VERSION ""

NS_ :

BS_:

BU_: MC_BRUSHED LISTENER COMMANDER REQUESTER

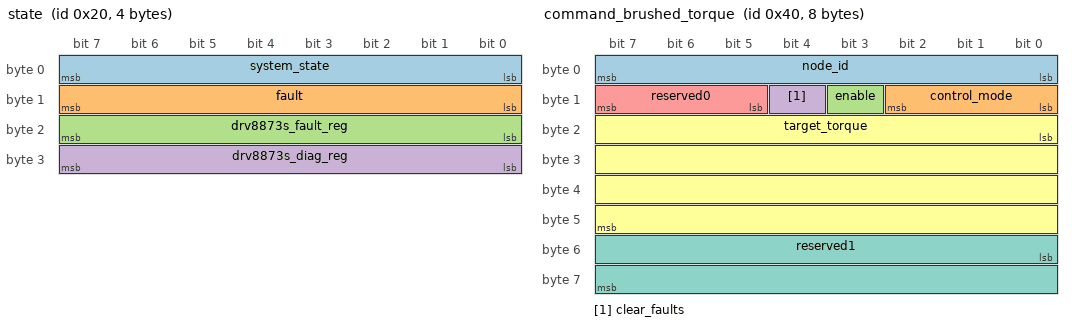
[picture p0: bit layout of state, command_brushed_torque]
BO_ 32 state: 4 MC_BRUSHED
 SG_ system_state : 0|8@1+ (1,0) [0|255] ""  LISTENER
 SG_ fault : 8|8@1+ (1,0) [0|255] ""  LISTENER
 SG_ drv8873s_fault_reg : 16|8@1+ (1,0) [0|255] ""  LISTENER
 SG_ drv8873s_diag_reg : 24|8@1+ (1,0) [0|255] ""  LISTENER

BO_ 64 command_brushed_torque: 8 COMMANDER
 SG_ node_id : 0|8@1+ (1,0) [0|255] ""  MC_BRUSHED
 SG_ control_mode : 8|3@1+ (1,0) [0|7] ""  MC_BRUSHED
 SG_ enable : 11|1@1+ (1,0) [0|1] ""  MC_BRUSHED
 SG_ clear_faults : 12|1@1+ (1,0) [0|1] ""  MC_BRUSHED
 SG_ reserved0 : 13|3@1+ (1,0) [0|7] ""  MC_BRUSHED
 SG_ target_torque : 16|32@1- (0.0001,0) [-214748.3648|214748.3647] "Nm"  MC_BRUSHED
 SG_ reserved1 : 48|16@1+ (1,0) [0|65535] ""  MC_BRUSHED

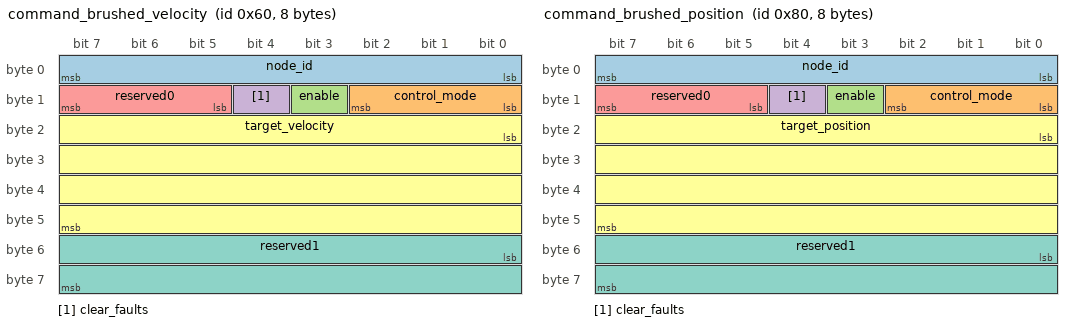
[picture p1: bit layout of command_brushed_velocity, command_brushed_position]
BO_ 96 command_brushed_velocity: 8 COMMANDER
 SG_ node_id : 0|8@1+ (1,0) [0|255] ""  MC_BRUSHED
 SG_ control_mode : 8|3@1+ (1,0) [0|7] ""  MC_BRUSHED
 SG_ enable : 11|1@1+ (1,0) [0|1] ""  MC_BRUSHED
 SG_ clear_faults : 12|1@1+ (1,0) [0|1] ""  MC_BRUSHED
 SG_ reserved0 : 13|3@1+ (1,0) [0|7] ""  MC_BRUSHED
 SG_ target_velocity : 16|32@1- (0.001,0) [-2147483.648|2147483.647] "rad/s"  MC_BRUSHED
 SG_ reserved1 : 48|16@1+ (1,0) [0|65535] ""  MC_BRUSHED

BO_ 128 command_brushed_position: 8 COMMANDER
 SG_ node_id : 0|8@1+ (1,0) [0|255] ""  MC_BRUSHED
 SG_ control_mode : 8|3@1+ (1,0) [0|7] ""  MC_BRUSHED
 SG_ enable : 11|1@1+ (1,0) [0|1] ""  MC_BRUSHED
 SG_ clear_faults : 12|1@1+ (1,0) [0|1] ""  MC_BRUSHED
 SG_ reserved0 : 13|3@1+ (1,0) [0|7] ""  MC_BRUSHED
 SG_ target_position : 16|32@1- (0.001,0) [-2147483.648|2147483.647] "rad"  MC_BRUSHED
 SG_ reserved1 : 48|16@1+ (1,0) [0|65535] ""  MC_BRUSHED

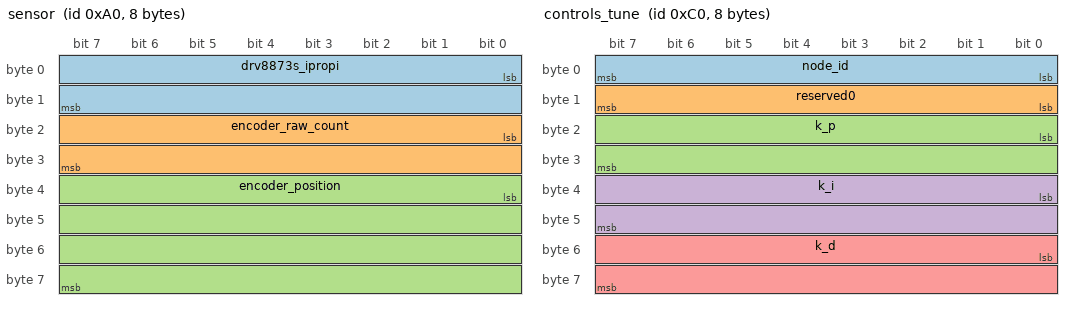
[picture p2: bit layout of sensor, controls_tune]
BO_ 160 sensor: 8 MC_BRUSHED
 SG_ drv8873s_ipropi : 0|16@1+ (1,0) [0|4095] "count"  LISTENER
 SG_ encoder_raw_count : 16|16@1- (1,0) [-32768|32767] "count"  LISTENER
 SG_ encoder_position : 32|32@1- (0.001,0) [-2147483.648|2147483.647] "rad"  LISTENER

BO_ 192 controls_tune: 8 COMMANDER
 SG_ node_id : 0|8@1+ (1,0) [0|255] ""  MC_BRUSHED
 SG_ reserved0 : 8|8@1+ (1,0) [0|255] ""  MC_BRUSHED
 SG_ k_p : 16|16@1+ (0.001,0) [0|65.535] ""  MC_BRUSHED
 SG_ k_i : 32|16@1+ (0.001,0) [0|65.535] ""  MC_BRUSHED
 SG_ k_d : 48|16@1+ (0.001,0) [0|65.535] ""  MC_BRUSHED

BO_ 224 controls_tune_get: 1 REQUESTER
 SG_ node_id : 0|8@1+ (1,0) [0|255] ""  MC_BRUSHED

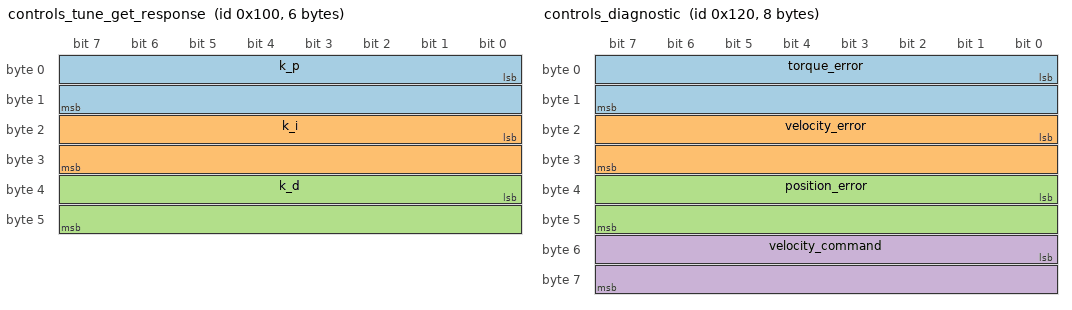
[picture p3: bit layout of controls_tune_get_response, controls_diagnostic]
BO_ 256 controls_tune_get_response: 6 MC_BRUSHED
 SG_ k_p : 0|16@1+ (0.001,0) [0|65.535] ""  REQUESTER
 SG_ k_i : 16|16@1+ (0.001,0) [0|65.535] ""  REQUESTER
 SG_ k_d : 32|16@1+ (0.001,0) [0|65.535] ""  REQUESTER

BO_ 288 controls_diagnostic: 8 MC_BRUSHED
 SG_ torque_error : 0|16@1- (0.001,0) [-32.768|32.767] "Nm"  LISTENER
 SG_ velocity_error : 16|16@1- (0.001,0) [-32.768|32.767] "rad/s"  LISTENER
 SG_ position_error : 32|16@1- (0.0001,0) [-3.2768|3.2767] "rad"  LISTENER
 SG_ velocity_command : 48|16@1- (0.001,0) [-32.768|32.767] "rad/s"  LISTENER

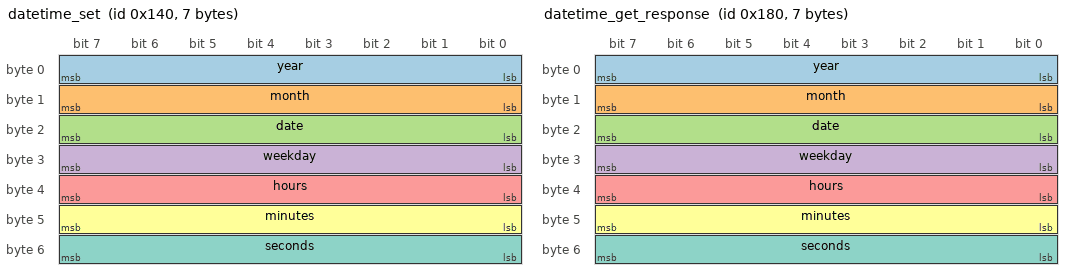
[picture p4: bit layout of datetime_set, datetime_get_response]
BO_ 320 datetime_set: 7 COMMANDER
 SG_ year : 0|8@1+ (1,0) [0|99] "year"  MC_BRUSHED
 SG_ month : 8|8@1+ (1,0) [1|12] "month"  MC_BRUSHED
 SG_ date : 16|8@1+ (1,0) [1|31] "day"  MC_BRUSHED
 SG_ weekday : 24|8@1+ (1,0) [1|7] "weekday"  MC_BRUSHED
 SG_ hours : 32|8@1+ (1,0) [0|23] "hour"  MC_BRUSHED
 SG_ minutes : 40|8@1+ (1,0) [0|59] "min"  MC_BRUSHED
 SG_ seconds : 48|8@1+ (1,0) [0|59] "sec"  MC_BRUSHED

BO_ 352 datetime_get: 0 REQUESTER

BO_ 384 datetime_get_response: 7 MC_BRUSHED
 SG_ year : 0|8@1+ (1,0) [0|99] "year"  REQUESTER
 SG_ month : 8|8@1+ (1,0) [1|12] "month"  REQUESTER
 SG_ date : 16|8@1+ (1,0) [1|31] "day"  REQUESTER
 SG_ weekday : 24|8@1+ (1,0) [1|7] "weekday"  REQUESTER
 SG_ hours : 32|8@1+ (1,0) [0|23] "hour"  REQUESTER
 SG_ minutes : 40|8@1+ (1,0) [0|59] "min"  REQUESTER
 SG_ seconds : 48|8@1+ (1,0) [0|59] "sec"  REQUESTER

BO_ 960 version_get: 0 REQUESTER

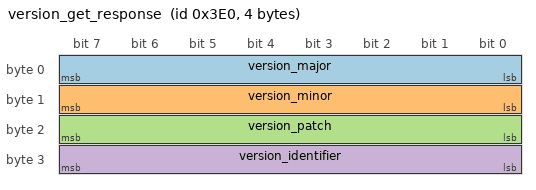
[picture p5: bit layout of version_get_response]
BO_ 992 version_get_response: 4 MC_BRUSHED
 SG_ version_major : 0|8@1+ (1,0) [0|255] "major"  REQUESTER
 SG_ version_minor : 8|8@1+ (1,0) [0|255] "minor"  REQUESTER
 SG_ version_patch : 16|8@1+ (1,0) [0|255] "patch"  REQUESTER
 SG_ version_identifier : 24|8@1+ (1,0) [0|255] "ascii"  REQUESTER

BA_DEF_  "BusType" STRING ;
BA_DEF_DEF_  "BusType" "CAN";
